VERSION ""

NS_ :

BS_:

BU_: Gateway ECM TCU ESC ADAS Cluster

BO_ 256 EngineStatus: 16 ECM
 SG_ EngineSpeed : 0|16@1+ (0.25,0) [0|8000] "rpm" Gateway,ADAS
 SG_ EngineCoolantTemp : 16|8@1+ (1,-40) [-40|150] "degC" Gateway,Cluster
 SG_ ThrottlePosition : 24|8@1+ (0.5,0) [0|100] "%" Gateway,TCU
 SG_ EngineTorque : 32|16@1- (0.5,0) [-500|1500] "Nm" Gateway,ESC
 SG_ FuelRate : 48|16@1+ (0.05,0) [0|100] "L/h" Gateway,Cluster

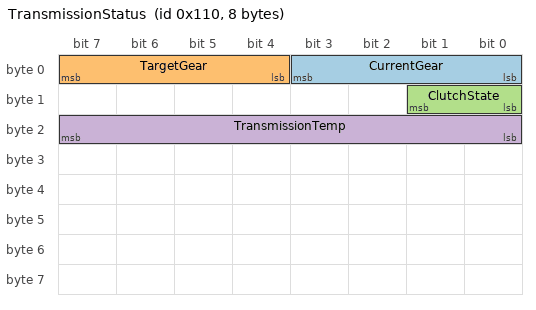
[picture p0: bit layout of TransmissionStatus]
BO_ 272 TransmissionStatus: 8 TCU
 SG_ CurrentGear : 0|4@1+ (1,0) [0|10] "" Gateway
 SG_ TargetGear : 4|4@1+ (1,0) [0|10] "" Gateway
 SG_ ClutchState : 8|2@1+ (1,0) [0|3] "" Gateway
 SG_ TransmissionTemp : 16|8@1+ (1,-40) [-40|160] "degC" Gateway

CM_ BO_ 256 "Primary powertrain telemetry broadcast at 10ms cycle time on CAN FD.";
CM_ SG_ 256 EngineSpeed "Crankshaft rotational speed in revolutions per minute.";
CM_ SG_ 256 EngineCoolantTemp "Engine coolant temperature with -40 degree Celsius offset.";
CM_ BO_ 272 "Automatic transmission control unit status broadcast at 20ms.";
